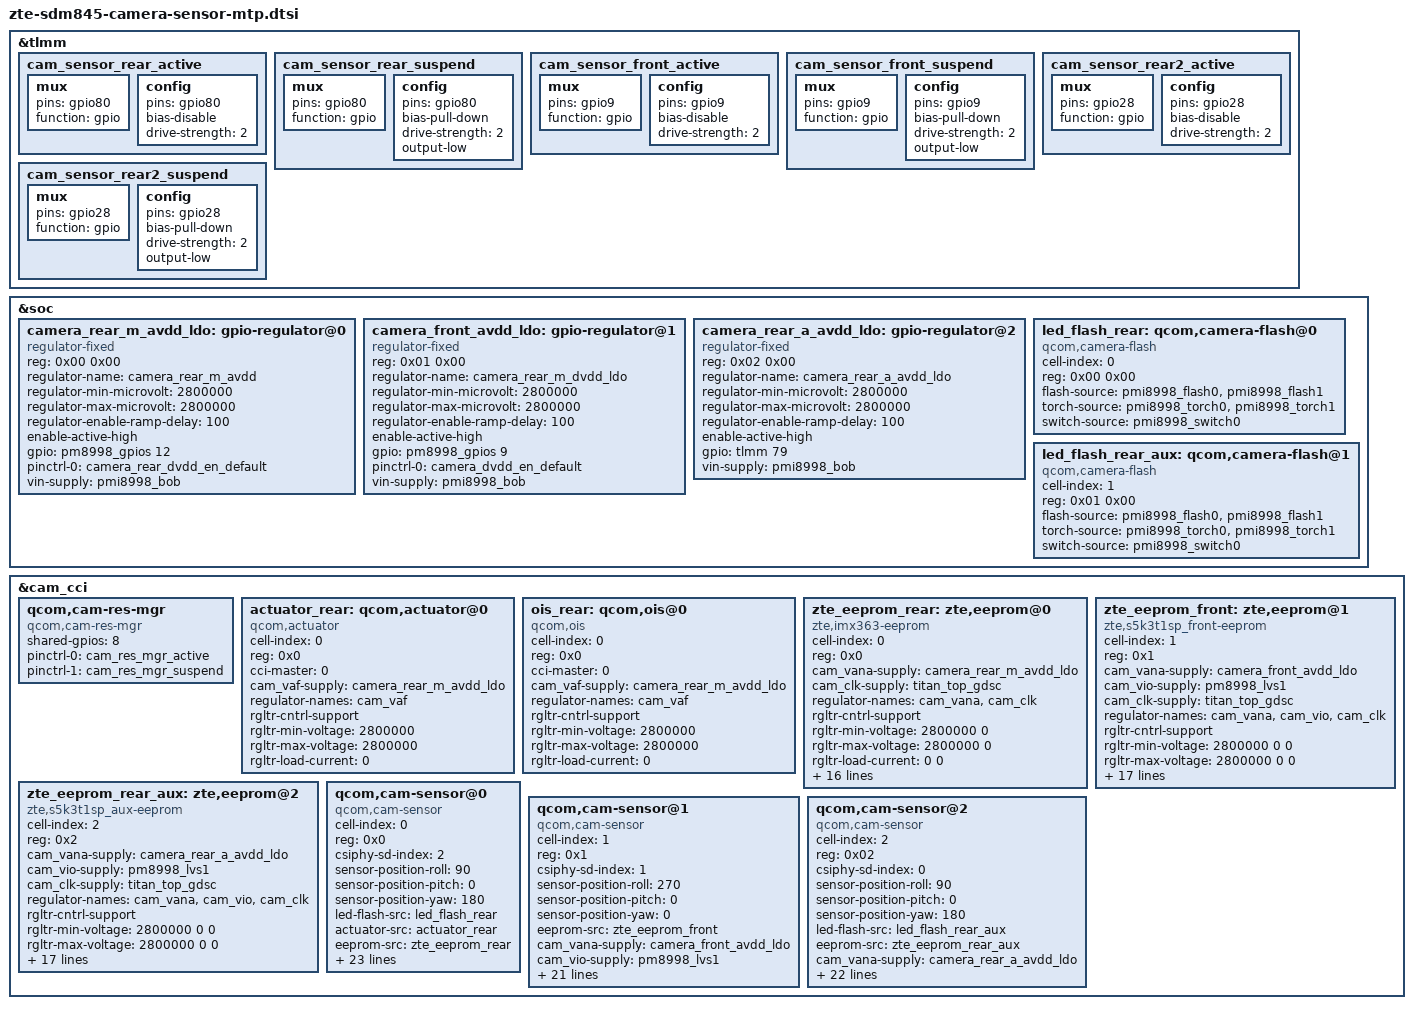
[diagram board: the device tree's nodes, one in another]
/*
 * Copyright (c) 2016-2017, The Linux Foundation. All rights reserved.
 *
 * This program is free software; you can redistribute it and/or modify
 * it under the terms of the GNU General Public License version 2 and
 * only version 2 as published by the Free Software Foundation.
 *
 * This program is distributed in the hope that it will be useful,
 * but WITHOUT ANY WARRANTY; without even the implied warranty of
 * MERCHANTABILITY or FITNESS FOR A PARTICULAR PURPOSE.  See the
 * GNU General Public License for more details.
 */


&tlmm {
		cam_sensor_rear_active: cam_sensor_rear_active {
			mux {
				pins = "gpio80";
				function = "gpio";
			};

			config {
				pins = "gpio80";
				bias-disable; /* No PULL */
				drive-strength = <2>; /* 2 MA */
			};
		};

		cam_sensor_rear_suspend: cam_sensor_rear_suspend {
			mux {
				pins = "gpio80";
				function = "gpio";
			};

			config {
				pins = "gpio80";
				bias-pull-down; /* PULL DOWN */
				drive-strength = <2>; /* 2 MA */
				output-low;
			};
		};

		cam_sensor_front_active: cam_sensor_front_active {
			mux {
				pins = "gpio9";
				function = "gpio";
			};

			config {
			pins = "gpio9";
			bias-disable; /* No PULL */
			drive-strength = <2>; /* 2 MA */
			};
		};

		cam_sensor_front_suspend: cam_sensor_front_suspend {
			mux {
				pins = "gpio9";
				function = "gpio";
			};

			config {
				pins = "gpio9";
				bias-pull-down; /* PULL DOWN */
				drive-strength = <2>; /* 2 MA */
				output-low;
			};
		};

		cam_sensor_rear2_active: cam_sensor_rear2_active {
			mux {
				pins = "gpio28";
				function = "gpio";
			};

			config {
				pins = "gpio28";
				bias-disable; /* No PULL */
				drive-strength = <2>; /* 2 MA */
			};
		};

		cam_sensor_rear2_suspend: cam_sensor_rear2_suspend {
			mux {
				pins = "gpio28";
				function = "gpio";
			};

			config {
				pins = "gpio28";
				bias-pull-down; /* PULL DOWN */
				drive-strength = <2>; /* 2 MA */
				output-low;
			};
		};
};

&soc {

	camera_rear_m_avdd_ldo: gpio-regulator@0 {
		compatible = "regulator-fixed";
		reg = <0x00 0x00>;
		regulator-name = "camera_rear_m_avdd";
		regulator-min-microvolt = <2800000>;
		regulator-max-microvolt = <2800000>;
		regulator-enable-ramp-delay = <100>;
		enable-active-high;
		gpio = <&pm8998_gpios 12 0>;
		pinctrl-names = "default";
		pinctrl-0 = <&camera_rear_dvdd_en_default>;
		vin-supply = <&pmi8998_bob>;
	};

	camera_front_avdd_ldo: gpio-regulator@1 {
		compatible = "regulator-fixed";
		reg = <0x01 0x00>;
		regulator-name = "camera_rear_m_dvdd_ldo";
		regulator-min-microvolt = <2800000>;
		regulator-max-microvolt = <2800000>;
		regulator-enable-ramp-delay = <100>;
		enable-active-high;
		gpio = <&pm8998_gpios 9 0>;
		pinctrl-names = "default";
		pinctrl-0 = <&camera_dvdd_en_default>;
		vin-supply = <&pmi8998_bob>;
	};

	camera_rear_a_avdd_ldo: gpio-regulator@2 {
		compatible = "regulator-fixed";
		reg = <0x02 0x00>;
		regulator-name = "camera_rear_a_avdd_ldo";
		regulator-min-microvolt = <2800000>;
		regulator-max-microvolt = <2800000>;
		regulator-enable-ramp-delay = <100>;
		enable-active-high;
		gpio = <&tlmm 79 0>;
		vin-supply = <&pmi8998_bob>;
	};

	led_flash_rear: qcom,camera-flash@0 {
		cell-index = <0>;
		reg = <0x00 0x00>;
		compatible = "qcom,camera-flash";
		flash-source = <&pmi8998_flash0 &pmi8998_flash1>;
		torch-source = <&pmi8998_torch0 &pmi8998_torch1>;
		switch-source = <&pmi8998_switch0>;
		status = "ok";
	};

	led_flash_rear_aux: qcom,camera-flash@1 {
		cell-index = <1>;
		reg = <0x01 0x00>;
		compatible = "qcom,camera-flash";
		flash-source = <&pmi8998_flash0 &pmi8998_flash1>;
		torch-source = <&pmi8998_torch0 &pmi8998_torch1>;
		switch-source = <&pmi8998_switch0>;
		status = "ok";
	};
};


&cam_cci {
	qcom,cam-res-mgr {
		compatible = "qcom,cam-res-mgr";
		status = "ok";
		shared-gpios = <8>;
		pinctrl-names = "cam_res_mgr_default", "cam_res_mgr_suspend";
		pinctrl-0 = <&cam_res_mgr_active>;
		pinctrl-1 = <&cam_res_mgr_suspend>;
	};

	actuator_rear: qcom,actuator@0 {
		cell-index = <0>;
		reg = <0x0>;
		compatible = "qcom,actuator";
		cci-master = <0>;
		cam_vaf-supply = <&camera_rear_m_avdd_ldo>;
		regulator-names = "cam_vaf";
		rgltr-cntrl-support;
		rgltr-min-voltage = <2800000>;
		rgltr-max-voltage = <2800000>;
		rgltr-load-current = <0>;
	};

	ois_rear: qcom,ois@0 {
		cell-index = <0>;
		reg = <0x0>;
		compatible = "qcom,ois";
		cci-master = <0>;
		cam_vaf-supply = <&camera_rear_m_avdd_ldo>;
		regulator-names = "cam_vaf";
		rgltr-cntrl-support;
		rgltr-min-voltage = <2800000>;
		rgltr-max-voltage = <2800000>;
		rgltr-load-current = <0>;
	};

	zte_eeprom_rear: zte,eeprom@0 {
		cell-index = <0>;
		reg = <0x0>;
		compatible = "zte,imx363-eeprom";
		cam_vana-supply = <&camera_rear_m_avdd_ldo>;
		cam_clk-supply = <&titan_top_gdsc>;
		regulator-names =  "cam_vana", "cam_clk";
		rgltr-cntrl-support;
		rgltr-min-voltage = <2800000 0>;
		rgltr-max-voltage = <2800000 0>;
		rgltr-load-current = <0 0>;
		gpio-no-mux = <0>;
		pinctrl-names = "cam_default", "cam_suspend";
		pinctrl-0 = <&cam_sensor_mclk2_active
				&cam_sensor_rear_active>;
		pinctrl-1 = <&cam_sensor_mclk2_suspend
				&cam_sensor_rear_suspend>;
		gpios = <&tlmm 15 0>,
			<&tlmm 80 0>;
		gpio-reset = <1>;
		gpio-req-tbl-num = <0 1>;
		gpio-req-tbl-flags = <1 0>;
		gpio-req-tbl-label = "CAMIF_MCLK2",
					"CAM_RESET0";
		sensor-position = <0>;
		sensor-mode = <0>;
		cci-master = <0>;
		status = "ok";
		clocks = <&clock_camcc CAM_CC_MCLK2_CLK>;
		clock-names = "cam_clk";
		clock-cntl-level = "turbo";
		clock-rates = <24000000>;
	};
	zte_eeprom_front: zte,eeprom@1 {
		cell-index = <1>;
		reg = <0x1>;
		compatible = "zte,s5k3t1sp_front-eeprom";
		cam_vana-supply = <&camera_front_avdd_ldo>;
		cam_vio-supply = <&pm8998_lvs1>;
		cam_clk-supply = <&titan_top_gdsc>;
		regulator-names = "cam_vana", "cam_vio", "cam_clk";
		rgltr-cntrl-support;
		rgltr-min-voltage = <2800000 0 0>;
		rgltr-max-voltage = <2800000 0 0>;
		rgltr-load-current = <0 0 0>;
		gpio-no-mux = <0>;
		pinctrl-names = "cam_default", "cam_suspend";
		pinctrl-0 = <&cam_sensor_mclk1_active
				&cam_sensor_front_active>;
		pinctrl-1 = <&cam_sensor_mclk1_suspend
				&cam_sensor_front_suspend>;
		gpios = <&tlmm 14 0>,
			<&tlmm 9 0>;
		gpio-reset = <1>;
		gpio-req-tbl-num = <0 1>;
		gpio-req-tbl-flags = <1 0>;
		gpio-req-tbl-label = "CAMIF_MCLK1",
					"CAM_RESET1";
		sensor-position = <1>;
		sensor-mode = <0>;
		cci-master = <1>;
		status = "ok";
		clocks = <&clock_camcc CAM_CC_MCLK1_CLK>;
		clock-names = "cam_clk";
		clock-cntl-level = "turbo";
		clock-rates = <24000000>;
	};
	zte_eeprom_rear_aux: zte,eeprom@2 {
		cell-index = <2>;
		reg = <0x2>;
		compatible = "zte,s5k3t1sp_aux-eeprom";
		cam_vana-supply = <&camera_rear_a_avdd_ldo>;
		cam_vio-supply = <&pm8998_lvs1>;
		cam_clk-supply = <&titan_top_gdsc>;
		regulator-names = "cam_vana", "cam_vio", "cam_clk";
		rgltr-cntrl-support;
		rgltr-min-voltage = <2800000 0 0>;
		rgltr-max-voltage = <2800000 0 0>;
		rgltr-load-current = <0 0 0>;
		gpio-no-mux = <0>;
		pinctrl-names = "cam_default", "cam_suspend";
		pinctrl-0 = <&cam_sensor_mclk0_active
				&cam_sensor_rear2_active>;
		pinctrl-1 = <&cam_sensor_mclk0_suspend
				&cam_sensor_rear2_suspend>;
		gpios = <&tlmm 13 0>,
			<&tlmm 28 0>;
		gpio-reset = <1>;
		gpio-req-tbl-num = <0 1>;
		gpio-req-tbl-flags = <1 0>;
		gpio-req-tbl-label = "CAMIF_MCLK0",
					"CAM_RESET2";
		sensor-position = <0>;
		sensor-mode = <0>;
		cci-master = <1>;
		status = "ok";
		clocks = <&clock_camcc CAM_CC_MCLK0_CLK>;
		clock-names = "cam_clk";
		clock-cntl-level = "turbo";
		clock-rates = <24000000>;
	};

	qcom,cam-sensor@0 {
		cell-index = <0>;
		compatible = "qcom,cam-sensor";
		reg = <0x0>;
		csiphy-sd-index = <2>;
		sensor-position-roll = <90>;
		sensor-position-pitch = <0>;
		sensor-position-yaw = <180>;
		led-flash-src = <&led_flash_rear>;
		actuator-src = <&actuator_rear>;
		eeprom-src = <&zte_eeprom_rear>;
		ois-src = <&ois_rear>;
		cam_vana-supply = <&camera_rear_m_avdd_ldo>;
		cam_clk-supply = <&titan_top_gdsc>;
		regulator-names =  "cam_vana", "cam_clk";
		rgltr-cntrl-support;
		rgltr-min-voltage = <2800000 0>;
		rgltr-max-voltage = <2800000 0>;
		rgltr-load-current = <0 0>;
		gpio-no-mux = <0>;
		pinctrl-names = "cam_default", "cam_suspend";
		pinctrl-0 = <&cam_sensor_mclk2_active
				&cam_sensor_rear_active>;
		pinctrl-1 = <&cam_sensor_mclk2_suspend
				&cam_sensor_rear_suspend>;
		gpios = <&tlmm 15 0>,
			<&tlmm 80 0>;
		gpio-reset = <1>;
		gpio-req-tbl-num = <0 1>;
		gpio-req-tbl-flags = <1 0>;
		gpio-req-tbl-label = "CAMIF_MCLK2",
					"CAM_RESET0";
		sensor-mode = <0>;
		cci-master = <0>;
		status = "ok";
		clocks = <&clock_camcc CAM_CC_MCLK2_CLK>;
		clock-names = "cam_clk";
		clock-cntl-level = "turbo";
		clock-rates = <24000000>;
	};

	qcom,cam-sensor@1 {
		cell-index = <1>;
		compatible = "qcom,cam-sensor";
		reg = <0x1>;
		csiphy-sd-index = <1>;
		sensor-position-roll = <270>;
		sensor-position-pitch = <0>;
		sensor-position-yaw = <0>;
		eeprom-src = <&zte_eeprom_front>;
		cam_vana-supply = <&camera_front_avdd_ldo>;
		cam_vio-supply = <&pm8998_lvs1>;
		cam_clk-supply = <&titan_top_gdsc>;
		regulator-names = "cam_vana", "cam_vio", "cam_clk";
		rgltr-cntrl-support;
		rgltr-min-voltage = <2800000 0 0>;
		rgltr-max-voltage = <2800000 0 0>;
		rgltr-load-current = <0 0 0>;
		gpio-no-mux = <0>;
		pinctrl-names = "cam_default", "cam_suspend";
		pinctrl-0 = <&cam_sensor_mclk1_active
				&cam_sensor_front_active>;
		pinctrl-1 = <&cam_sensor_mclk1_suspend
				&cam_sensor_front_suspend>;
		gpios = <&tlmm 14 0>,
			<&tlmm 9 0>;
		gpio-reset = <1>;
		gpio-req-tbl-num = <0 1>;
		gpio-req-tbl-flags = <1 0>;
		gpio-req-tbl-label = "CAMIF_MCLK1",
					"CAM_RESET1";
		sensor-mode = <0>;
		cci-master = <1>;
		status = "ok";
		clocks = <&clock_camcc CAM_CC_MCLK1_CLK>;
		clock-names = "cam_clk";
		clock-cntl-level = "turbo";
		clock-rates = <24000000>;
	};

	qcom,cam-sensor@2 {
		cell-index = <2>;
		compatible = "qcom,cam-sensor";
		reg = <0x02>;
		csiphy-sd-index = <0>;
		sensor-position-roll = <90>;
		sensor-position-pitch = <0>;
		sensor-position-yaw = <180>;
		led-flash-src = <&led_flash_rear_aux>;
		eeprom-src = <&zte_eeprom_rear_aux>;
		cam_vana-supply = <&camera_rear_a_avdd_ldo>;
		cam_vio-supply = <&pm8998_lvs1>;
		cam_clk-supply = <&titan_top_gdsc>;
		regulator-names = "cam_vana", "cam_vio", "cam_clk";
		rgltr-cntrl-support;
		rgltr-min-voltage = <2800000 0 0>;
		rgltr-max-voltage = <2800000 0 0>;
		rgltr-load-current = <0 0 0>;
		gpio-no-mux = <0>;
		pinctrl-names = "cam_default", "cam_suspend";
		pinctrl-0 = <&cam_sensor_mclk0_active
				&cam_sensor_rear2_active>;
		pinctrl-1 = <&cam_sensor_mclk0_suspend
				&cam_sensor_rear2_suspend>;
		gpios = <&tlmm 13 0>,
			<&tlmm 28 0>;
		gpio-reset = <1>;
		gpio-req-tbl-num = <0 1>;
		gpio-req-tbl-flags = <1 0>;
		gpio-req-tbl-label = "CAMIF_MCLK0",
					"CAM_RESET2";
		sensor-mode = <0>;
		cci-master = <1>;
		status = "ok";
		clocks = <&clock_camcc CAM_CC_MCLK0_CLK>;
		clock-names = "cam_clk";
		clock-cntl-level = "turbo";
		clock-rates = <24000000>;
	};

};
